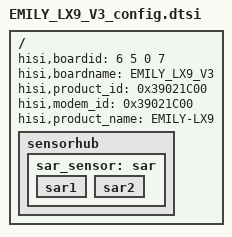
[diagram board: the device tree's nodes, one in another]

/**
 * Copyright (C) 2014 Hisilicon Ltd.
 *
 *  This program is free software; you can redistribute it and/or modify
 *  it under the terms of the GNU General Public License version 2 as
 *  publishhed by the Free Software Foundation.
 */

/include/ "EMILY_TUGL_V1_config.dtsi"

/ {
	hisi,boardid = <6 5 0 7>;
	hisi,boardname = "EMILY_LX9_V3";
	hisi,product_id = <0x39021C00>;
	hisi,modem_id = <0x39021C00>;
	hisi,product_name = "EMILY-LX9";
	sensorhub{
		sar_sensor:sar{
			sar1{
				status = "ok";
			};
			sar2{
				status = "ok";
			};
		};
	};
};
